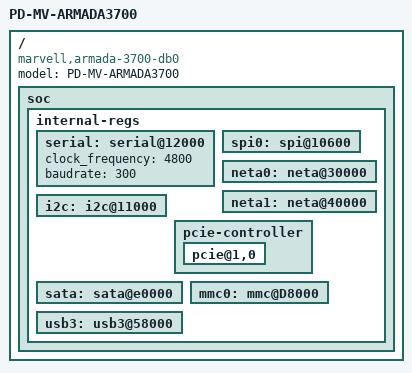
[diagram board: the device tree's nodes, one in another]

/dts-v1/;

#include "armada-3700.dtsi"

/ {
	model = "PD-MV-ARMADA3700";
	compatible = "marvell,armada-3700-db0", "marvell,armada-3700";

	soc {
		internal-regs {
			serial: serial@12000 {
				clock_frequency = <4800>;
				baudrate = <300>;
				status = "okay";
			};
			spi0: spi@10600 {
				status = "okay";
			};
			neta0: neta@30000 {
				status = "okay";
			};
			neta1: neta@40000 {
				status = "okay";
			};
			i2c: i2c@11000 {
				status = "okay";
			};
			pcie-controller {
				pcie@1,0 {
					status = "okay";
				};
			};
			sata: sata@e0000 {
				status = "okay";
			};
			mmc0: mmc@D8000 {
				status = "okay";
			};
			usb3: usb3@58000 {
				status = "okay";
			};
		};
	};
};
